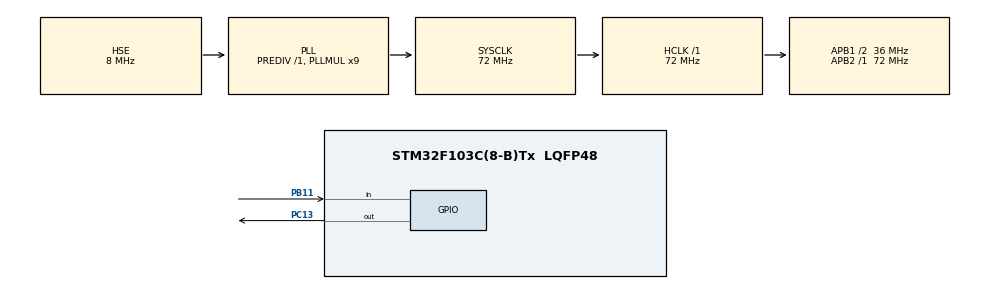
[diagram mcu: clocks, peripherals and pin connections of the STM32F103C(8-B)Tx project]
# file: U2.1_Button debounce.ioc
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Mcu.Family=STM32F1
Mcu.Name=STM32F103C(8-B)Tx
Mcu.Package=LQFP48
NVIC.PriorityGroup=NVIC_PRIORITYGROUP_4
PA13.Mode=Serial_Wire
PA13.Signal=SYS_JTMS-SWDIO
PA14.Mode=Serial_Wire
PA14.Signal=SYS_JTCK-SWCLK
PB11.GPIO_PuPd=GPIO_PULLUP
PB11.Signal=GPIO_Input
PC13-TAMPER-RTC.Signal=GPIO_Output
PD0-OSC_IN.Mode=HSE-External-Oscillator
PD0-OSC_IN.Signal=RCC_OSC_IN
PD1-OSC_OUT.Mode=HSE-External-Oscillator
PD1-OSC_OUT.Signal=RCC_OSC_OUT
ProjectManager.HeapSize=0x200
ProjectManager.StackSize=0x400
ProjectManager.TargetToolchain=STM32CubeIDE
RCC.AHBFreq_Value=72000000
RCC.APB1CLKDivider=RCC_HCLK_DIV2
RCC.APB1Freq_Value=36000000
RCC.APB1TimFreq_Value=72000000
RCC.APB2Freq_Value=72000000
RCC.APB2TimFreq_Value=72000000
RCC.HCLKFreq_Value=72000000
RCC.PLLMUL=RCC_PLL_MUL9
RCC.PLLSourceVirtual=RCC_PLLSOURCE_HSE
RCC.SYSCLKFreq_VALUE=72000000
RCC.SYSCLKSource=RCC_SYSCLKSOURCE_PLLCLK
RCC.USBFreq_Value=72000000
board=custom

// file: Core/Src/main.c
/* USER CODE BEGIN Header */
/**
  ******************************************************************************
  * @file           : main.c
  * @brief          : Main program body
  ******************************************************************************
  * @attention
  *
  * Copyright (c) 2022 STMicroelectronics.
  * All rights reserved.
  *
  * This software is licensed under terms that can be found in the LICENSE file
  * in the root directory of this software component.
  * If no LICENSE file comes with this software, it is provided AS-IS.
  *
  ******************************************************************************
  */
/* USER CODE END Header */
#include "main.h"

void SystemClock_Config(void);
static void MX_GPIO_Init(void);

/* USER CODE BEGIN 0 */
//========== var btn ==========//
uint8_t btn_current = 1;
uint8_t btn_last = 1;
uint8_t btn_filter = 1;
uint8_t is_debouncing = 0;
uint8_t is_press_long = 0;
uint32_t time_debounce;
uint32_t time_start_press;

//========== var led ==========//
typedef enum{
	LED_OFF,
	LED_BLINK_1HZ,
	LED_BLINK_5HZ,
} LedStatus;

LedStatus led_status;

//========== btn func ==========//
void btn_pressing_callback(){
	switch(led_status){
	case LED_OFF:
		led_status = LED_BLINK_1HZ;
		break;
	case LED_BLINK_1HZ:
		led_status = LED_BLINK_5HZ;
		break;
	case LED_BLINK_5HZ:
		led_status = LED_OFF;
		break;
	}
}

void btn_release_callback(){
//	HAL_GPIO_WritePin(GPIOC, GPIO_PIN_13, GPIO_PIN_SET);
	;
}

void btn_press_short_callback(){
//	HAL_GPIO_TogglePin(GPIOC, GPIO_PIN_13);
//	HAL_Delay(100);
//	HAL_GPIO_TogglePin(GPIOC, GPIO_PIN_13);
//	HAL_Delay(100);
	;
}

void btn_press_long_callback(){
//	HAL_GPIO_TogglePin(GPIOC, GPIO_PIN_13);
//	HAL_Delay(100);
//	HAL_GPIO_TogglePin(GPIOC, GPIO_PIN_13);
//	HAL_Delay(100);
//	HAL_GPIO_TogglePin(GPIOC, GPIO_PIN_13);
//	HAL_Delay(100);
//	HAL_GPIO_TogglePin(GPIOC, GPIO_PIN_13);
//	HAL_Delay(100);
	;
}

void button_handle(){
	uint8_t state = HAL_GPIO_ReadPin(GPIOB, GPIO_PIN_11);
	if(state != btn_filter){
		btn_filter = state;
		is_debouncing = 1;
		time_debounce = HAL_GetTick();
	}

	if(is_debouncing && (HAL_GetTick() - time_debounce >= 15)){
		btn_current = btn_filter;
		is_debouncing = 0;
	}

	if(btn_current != btn_last){
		if(btn_current == 0){
			btn_pressing_callback();
			is_press_long = 1;
			time_start_press = HAL_GetTick();
		}
		else{
			if(HAL_GetTick() - time_start_press <= 1000){
				btn_press_short_callback();
			}
			btn_release_callback();
		}
		btn_last = btn_current;
	}

	if(is_press_long && (HAL_GetTick() - time_start_press >= 3000)){
		btn_press_long_callback();
		is_press_long = 0;
	}
}

//========== led func ==========//
void led_off(){
	HAL_GPIO_WritePin(GPIOC, GPIO_PIN_13, GPIO_PIN_SET);
}

void led_blink_1hz(){
	static uint32_t time_led_blink_1hz;
	if(HAL_GetTick() - time_led_blink_1hz >= 500){
		HAL_GPIO_TogglePin(GPIOC, GPIO_PIN_13);
		time_led_blink_1hz = HAL_GetTick();
	}
}

void led_blink_5hz(){
	static uint32_t time_led_blink_5hz;
	if(HAL_GetTick() - time_led_blink_5hz >= 100){
		HAL_GPIO_TogglePin(GPIOC, GPIO_PIN_13);
		time_led_blink_5hz = HAL_GetTick();
	}
}

void led_handle(){
	switch(led_status){
	case LED_OFF:
		led_off();
		break;
	case LED_BLINK_1HZ:
		led_blink_1hz();
		break;
	case LED_BLINK_5HZ:
		led_blink_5hz();
		break;
	}
}

/* USER CODE END 0 */

int main(void)
{

  /* MCU Configuration--------------------------------------------------------*/

  /* Reset of all peripherals, Initializes the Flash interface and the Systick. */
  HAL_Init();

  /* Configure the system clock */
  SystemClock_Config();

  /* Initialize all configured peripherals */
  MX_GPIO_Init();
  /* USER CODE BEGIN 2 */
  HAL_GPIO_WritePin(GPIOC, GPIO_PIN_13, GPIO_PIN_SET);
  /* USER CODE END 2 */

  /* Infinite loop */
  while (1)
  {

    /* USER CODE BEGIN 3 */
	  button_handle();
	  led_handle();
  }
  /* USER CODE END 3 */
}

void SystemClock_Config(void)
{
  RCC_OscInitTypeDef RCC_OscInitStruct = {0};
  RCC_ClkInitTypeDef RCC_ClkInitStruct = {0};

  /** Initializes the RCC Oscillators according to the specified parameters
  * in the RCC_OscInitTypeDef structure.
  */
  RCC_OscInitStruct.OscillatorType = RCC_OSCILLATORTYPE_HSE;
  RCC_OscInitStruct.HSEState = RCC_HSE_ON;
  RCC_OscInitStruct.HSEPredivValue = RCC_HSE_PREDIV_DIV1;
  RCC_OscInitStruct.HSIState = RCC_HSI_ON;
  RCC_OscInitStruct.PLL.PLLState = RCC_PLL_ON;
  RCC_OscInitStruct.PLL.PLLSource = RCC_PLLSOURCE_HSE;
  RCC_OscInitStruct.PLL.PLLMUL = RCC_PLL_MUL9;
  if (HAL_RCC_OscConfig(&RCC_OscInitStruct) != HAL_OK)
  {
    Error_Handler();
  }
  /** Initializes the CPU, AHB and APB buses clocks
  */
  RCC_ClkInitStruct.ClockType = RCC_CLOCKTYPE_HCLK|RCC_CLOCKTYPE_SYSCLK
                              |RCC_CLOCKTYPE_PCLK1|RCC_CLOCKTYPE_PCLK2;
  RCC_ClkInitStruct.SYSCLKSource = RCC_SYSCLKSOURCE_PLLCLK;
  RCC_ClkInitStruct.AHBCLKDivider = RCC_SYSCLK_DIV1;
  RCC_ClkInitStruct.APB1CLKDivider = RCC_HCLK_DIV2;
  RCC_ClkInitStruct.APB2CLKDivider = RCC_HCLK_DIV1;

  if (HAL_RCC_ClockConfig(&RCC_ClkInitStruct, FLASH_LATENCY_2) != HAL_OK)
  {
    Error_Handler();
  }
}

static void MX_GPIO_Init(void)
{
  GPIO_InitTypeDef GPIO_InitStruct = {0};

  /* GPIO Ports Clock Enable */
  __HAL_RCC_GPIOC_CLK_ENABLE();
  __HAL_RCC_GPIOD_CLK_ENABLE();
  __HAL_RCC_GPIOB_CLK_ENABLE();
  __HAL_RCC_GPIOA_CLK_ENABLE();

  /*Configure GPIO pin Output Level */
  HAL_GPIO_WritePin(GPIOC, GPIO_PIN_13, GPIO_PIN_RESET);

  /*Configure GPIO pin : PC13 */
  GPIO_InitStruct.Pin = GPIO_PIN_13;
  GPIO_InitStruct.Mode = GPIO_MODE_OUTPUT_PP;
  GPIO_InitStruct.Pull = GPIO_NOPULL;
  GPIO_InitStruct.Speed = GPIO_SPEED_FREQ_LOW;
  HAL_GPIO_Init(GPIOC, &GPIO_InitStruct);

  /*Configure GPIO pin : PB11 */
  GPIO_InitStruct.Pin = GPIO_PIN_11;
  GPIO_InitStruct.Mode = GPIO_MODE_INPUT;
  GPIO_InitStruct.Pull = GPIO_PULLUP;
  HAL_GPIO_Init(GPIOB, &GPIO_InitStruct);

}

void Error_Handler(void)
{
  __disable_irq();
  while (1)
  {
  }
}
